# cslr_seq_001 register map
Vendor: Texas Instruments
Peripheral module from a debugger description file.
Registers are 32-bit, access not given, reset 0x0 unless marked. A register's access mark holds for its fields unless they carry their own. Offsets are as the file gives them; lines under a group give offsets from that group; [hi:lo] are bit positions; {n}, {i} and the like mark numbered series; 'fields as' and 'values as' point back to an identical list; <NAME> marks a mode.

## SEQ — DaVinci - Sequencer Control Registers
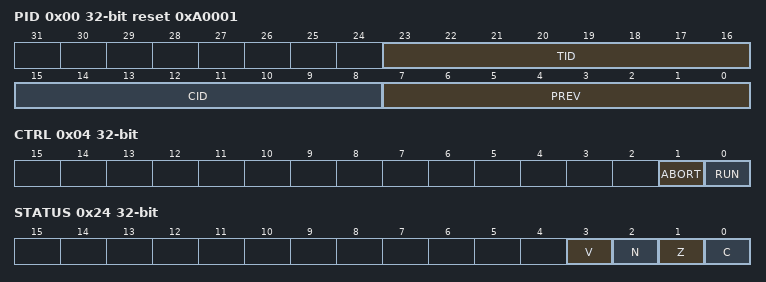
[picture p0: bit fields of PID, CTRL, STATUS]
0x00 PID reset 0xA0001 — Sequencer control register
  [23:16] TID ro — \hPeripheral ID. 0x0A - Sequencer Module
  [15:8] CID ro — \hClass ID. Standard ALU
  [7:0] PREV ro — \hPeripheral Revision Number
0x04 CTRL — Sequencer control register
  [1] ABORT rw — \hSequencer abort control: Note: Abort is equivalent to stop command in assembly
    0=RUNNING; 1=ABORT
  [0] RUN rw — \hSequencer run control:
    0=IDLE; 1=START
0x08 BOOT — Sequencer boot address register
  [10:0] ADDR rw — \hSequencer Boot address. Sequencer will start executing by fetching the first instruction from this address
0x0C AREG — A register of Sequencer (debug)
  [15:0] AREG ro — \hSequencer A register contents. Note: Should only be read if sequencer is halted using Sync or Stop command
0x10 BREG — B register of Sequencer (debug)
  [15:0] BREG ro — \hSequencer B register contents. Note: Should only be read if sequencer is halted using Sync or Stop command
0x14 CREG — C register of Sequencer (debug)
  [15:0] CREG ro — \hSequencer C register contents. Note: Should only be read if sequencer is halted using Sync or Stop command
0x18 PREG — P1 register of Sequencer (debug)
  [15:0] P1REG ro — \hSequencer P1 register contents. Note: Should only be read if sequencer is halted using Sync or Stop command
0x1C P2REG — P2 register of Sequencer (debug)
  [15:0] P2REG ro — \hSequencer P2 register contents. Note: Should only be read if sequencer is halted using Sync or Stop command
0x20 PCREG — PC register of Sequencer (debug)
  [15:0] PCREG ro — \hSequencer PC register contents. Note: Should only be read if sequencer is halted using Sync or Stop command
0x24 STATUS — Status register of Sequencer (debug)
  [3] V ro — Overflow Status Bit
    0=NOOVERFLOW (Arithmetic instruction casued no overflow); 1=OVERFLOW (Arithmetic instruction casued an overflow)
  [2] N ro — Negative Status Bit
    0=NON_NEGATIVE (Data value last loaded into a register had MSB '0'); 1=NEGATIVE (Data value last loaded into a register had MSB '1')
  [1] Z ro — Zero Status Bit
    0=NONZERO (Data value last loaded into a register was non-zero); 1=ZERO (Data value last loaded into a register was zero)
  [0] C ro — Arithmetic Carry Status Bit
    0=NOCARRY (Arithmetic instruction casued no carry); 1=CARRY (Arithmetic instruction casued a carry)
